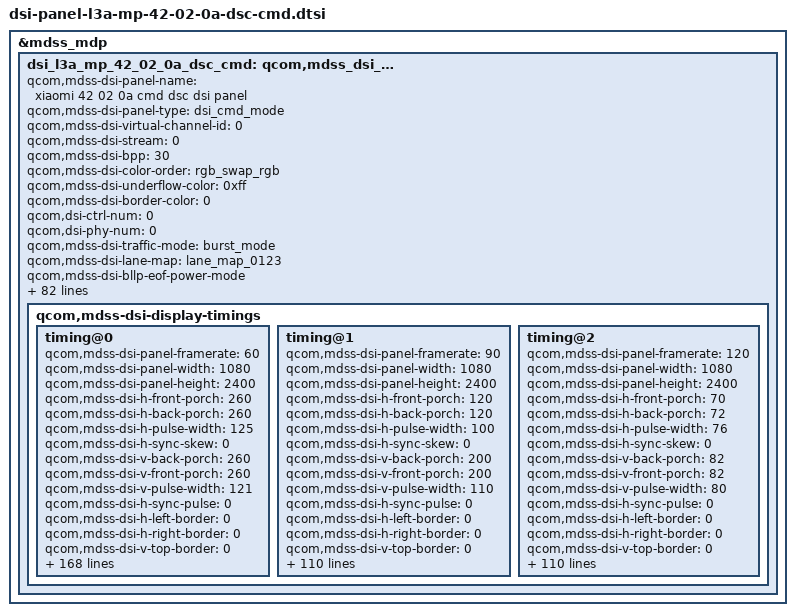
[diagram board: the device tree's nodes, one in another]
&mdss_mdp {
	dsi_l3a_mp_42_02_0a_dsc_cmd: qcom,mdss_dsi_l3a_mp_42_02_0a_dsc_cmd {
		qcom,mdss-dsi-panel-name = "xiaomi 42 02 0a cmd dsc dsi panel";
		qcom,mdss-dsi-panel-type = "dsi_cmd_mode";
		qcom,mdss-dsi-virtual-channel-id = <0>;
		qcom,mdss-dsi-stream = <0>;
		qcom,mdss-dsi-bpp = <30>;
		qcom,mdss-dsi-color-order = "rgb_swap_rgb";
		qcom,mdss-dsi-underflow-color = <0xff>;
		qcom,mdss-dsi-border-color = <0>;

		qcom,dsi-ctrl-num = <0>;
		qcom,dsi-phy-num = <0>;

		qcom,mdss-dsi-traffic-mode = "burst_mode";
		qcom,mdss-dsi-lane-map = "lane_map_0123";
		qcom,mdss-dsi-bllp-eof-power-mode;
		qcom,mdss-dsi-bllp-power-mode;
		qcom,mdss-dsi-lane-0-state;
		qcom,mdss-dsi-lane-1-state;
		qcom,mdss-dsi-lane-2-state;
		qcom,mdss-dsi-lane-3-state;
		qcom,mdss-dsi-dma-trigger = "trigger_sw";
		qcom,mdss-dsi-mdp-trigger = "none";
		qcom,mdss-dsi-reset-sequence = <1 1>, <0 1>, <1 10>;
		qcom,mdss-pan-physical-width-dimension = <654>;
		qcom,mdss-pan-physical-height-dimension = <1454>;
		qcom,mdss-dsi-te-pin-select = <1>;
		qcom,mdss-dsi-wr-mem-start = <0x2c>;
		qcom,mdss-dsi-wr-mem-continue = <0x3c>;
		qcom,mdss-dsi-te-dcs-command = <1>;
		qcom,mdss-dsi-te-check-enable;
		qcom,mdss-dsi-te-using-te-pin;
		qcom,mdss-dsi-tx-eot-append;
		qcom,mdss-dsi-lp11-init;

		qcom,mdss-dsi-panel-hdr-enabled;
		qcom,mdss-dsi-panel-hdr-color-primaries = <14500 15500 32000
			17000 15500 30000 8000 3000>;
		qcom,mdss-dsi-panel-peak-brightness = <4200000>;
		qcom,mdss-dsi-panel-blackness-level = <3230>;

		qcom,bl-update-flag = "delay_until_first_frame";

		qcom,esd-check-enabled;
		qcom,mdss-dsi-panel-status-check-mode = "reg_read";
		qcom,mdss-dsi-panel-status-offset-command = [
			39 00 00 00 00 00 05 FF AA 55 A5 81
			15 01 00 00 00 00 02 6F 0F];
		qcom,mdss-dsi-panel-status-command = [
			06 01 00 01 00 00 01 FA
			06 01 00 01 00 00 01 91];
		qcom,mdss-dsi-panel-status-read-length = <1 18>;
		qcom,mdss-dsi-panel-max-error-count = <3>;
		qcom,mdss-dsi-panel-status-value = <0x00>,
				<0xAB 0x28 0x00 0x0C 0xC2 0x00 0x03 0x1C 0x01 0x7E 0x00 0x0F 0x08 0xBB 0x04 0x3D 0x10 0xF0>;
		qcom,mdss-dsi-panel-status-command-state = "dsi_lp_mode";
		qcom,mdss-dsi-panel-status-offset-command-state = "dsi_lp_mode";

		qcom,mdss-dsi-display-timings {
			timing@0{
				qcom,mdss-dsi-panel-framerate = <60>;
				qcom,mdss-dsi-panel-width = <1080>;
				qcom,mdss-dsi-panel-height = <2400>;
				qcom,mdss-dsi-h-front-porch = <260>;
				qcom,mdss-dsi-h-back-porch = <260>;
				qcom,mdss-dsi-h-pulse-width = <125>;
				qcom,mdss-dsi-h-sync-skew = <0>;
				qcom,mdss-dsi-v-back-porch = <260>;
				qcom,mdss-dsi-v-front-porch = <260>;
				qcom,mdss-dsi-v-pulse-width = <121>;
				qcom,mdss-dsi-h-sync-pulse = <0>;
				qcom,mdss-dsi-h-left-border = <0>;
				qcom,mdss-dsi-h-right-border = <0>;
				qcom,mdss-dsi-v-top-border = <0>;
				qcom,mdss-dsi-v-bottom-border = <0>;
				qcom,mdss-dsi-panel-clockrate = <1100000000>;
				qcom,mdss-dsi-panel-jitter = <0x5 0x1>;
				qcom,mdss-mdp-transfer-time-us = <8000>;
				qcom,mdss-dsi-on-command = [
					39 00 00 00 00 00 06 F0 55 AA 52 08 00
					15 00 00 00 00 00 02 6F 29
					15 00 00 00 00 00 02 D9 00
					15 00 00 00 00 00 02 6F 01
					15 00 00 00 00 00 02 D9 80
					15 00 00 00 00 00 02 6F 07
					39 00 00 00 00 00 03 B2 07 FF
					15 00 00 00 00 00 02 6F 17
					39 00 00 00 00 00 03 B2 07 FF
					15 00 00 00 00 00 02 6F 1F
					39 01 00 00 00 00 03 B2 00 50
					39 00 00 00 00 00 06 F0 55 AA 52 08 07
					/*round for FPR*/
					39 00 00 00 00 00 2C C9 21 00 27 D9 27 D9 00 00 3F E0 8E C6 3F E0 8E C6 80 06 33 D5 F1 00 16 13 00 7B 78 33 D0 27 D9 0F 9B 9B 00 00 00 00 00 00 00 00 00
					39 00 00 00 00 00 2C CA 27 00 27 D9 27 D9 00 00 00 00 00 00 3F E0 8E C6 80 00 00 00 00 00 7C 13 00 E1 78 33 D0 00 00 03 65 9B 00 00 00 00 00 00 00 00 00
					39 00 00 00 00 00 2C CB 2D 00 27 D9 27 D9 00 00 3F E0 8E C6 80 00 00 00 00 00 00 00 00 00 16 79 00 7B DE 33 70 00 00 0C 9B 65 00 00 00 00 00 00 00 00 00
					39 01 00 00 00 00 2C CC 2B 00 27 D9 27 D9 00 00 00 00 00 00 80 00 00 00 7F F9 CC 2A 0F 00 7C 79 00 E1 DE 33 7F D8 27 00 65 65 00 00 00 00 00 00 00 00 00
					39 00 00 00 00 00 02 CD 00
					39 00 00 00 00 00 02 CE 00
					39 00 00 00 00 00 02 CF 00
					39 01 00 00 00 00 02 D0 00
					39 00 00 00 00 00 02 C1 00
					39 00 00 00 00 00 02 C2 00
					39 00 00 00 00 00 02 C3 00
					39 00 00 00 00 00 02 C4 00
					39 00 00 00 00 00 02 C5 00
					39 00 00 00 00 00 02 C6 00
					39 00 00 00 00 00 02 C7 00
					39 01 00 00 00 00 02 C8 00
					39 01 00 00 00 00 03 C0 05 02
					15 00 00 00 00 00 02 90 01	// VESA ON
					/* Choose VESA Edition */
					39 00 00 00 00 00 13 91	AB 28 00 0C C2 00 03 1C 01 7E 00 0F 08 BB 04 3D 10 F0	// DSC Setting
					15 01 00 00 00 00 02 03 01
					15 01 00 00 00 00 02 35 00	// TE ON
					39 01 00 00 00 00 05 2A 00 00 04 37
					39 01 00 00 00 00 05 2B 00 00 09 5F
					15 01 00 00 00 00 02 53 20
					15 01 00 00 00 00 02 2F 01
					15 01 00 00 00 00 02 26 01
					39 00 00 00 00 00 06 F0 55 AA 52 08 01
					39 01 00 00 00 00 08 C3 9B 01 94 D0 22 02 00
					39 01 00 00 00 00 05 FF AA 55 A5 80
					39 01 00 00 00 00 02 6F 61
					39 01 00 00 00 00 02 F3 80
					39 01 00 00 00 00 06 F0 55 AA 52 08 00
					39 01 00 00 00 00 02 C0 46
					39 01 00 00 00 00 02 6F 08
					39 01 00 00 00 00 02 B5 32
					39 01 00 00 00 00 02 6F 0B
					39 01 00 00 00 00 04 B5 33 23 2B
					39 01 00 00 00 00 06 F0 55 AA 52 08 01
					39 01 00 00 00 00 02 6F 01
					39 01 00 00 00 00 04 D2 00 00 11
					39 01 00 00 00 00 02 6F 06
					39 01 00 00 00 00 02 D2 05
					39 01 00 00 00 00 02 6F 0F
					39 01 00 00 00 00 02 D2 00
					39 01 00 00 00 00 02 6F 09
					39 01 00 00 00 00 03 D2 00 00
					39 01 00 00 00 00 02 CE 00
					39 01 00 00 00 00 06 F0 55 AA 52 08 05
					39 00 00 00 00 00 02 CA 11
					39 01 00 00 00 00 04 CB 22 22 22
					/* Sleep Out */
					05 01 00 00 50 00 02 11 00
					/* Display On */
					05 01 00 00 00 00 02 29 00];
				qcom,mdss-dsi-off-command = [
					05 01 00 00 00 00 02 28 00
					05 01 00 00 78 00 02 10 00];
				qcom,mdss-dsi-on-command-state = "dsi_lp_mode";
				qcom,mdss-dsi-off-command-state = "dsi_lp_mode";

				qcom,mdss-dsi-timing-switch-command = [
					/* Enter 60Hz */
					15 01 00 00 00 00 02 2F 01
					15 01 00 00 00 00 02 26 01];
				qcom,mdss-dsi-timing-switch-command-state = "dsi_lp_mode";

				qcom,mdss-dsi-nolp-command = [
					/* Aod to Normal */
					39 01 00 00 00 00 06 F0 55 AA 52 08 00 /* Set page 0 */
					39 01 00 00 00 00 02 B2 18
					05 01 00 00 00 00 02 38 00];
				qcom,mdss-dsi-nolp-command-state = "dsi_lp_mode";

				qcom,compression-mode = "dsc";
				qcom,mdss-dsc-version = <0x11>;
				qcom,mdss-dsc-scr-version = <0x0>;
				qcom,mdss-dsc-slice-height = <12>;
				qcom,mdss-dsc-slice-width = <1080>;
				qcom,mdss-dsc-slice-per-pkt = <2>;
				qcom,mdss-dsc-bit-per-component = <10>;
				qcom,mdss-dsc-bit-per-pixel = <8>;
				qcom,mdss-dsc-block-prediction-enable;
			};
			timing@1{
				qcom,mdss-dsi-panel-framerate = <90>;
				qcom,mdss-dsi-panel-width = <1080>;
				qcom,mdss-dsi-panel-height = <2400>;
				qcom,mdss-dsi-h-front-porch = <120>;
				qcom,mdss-dsi-h-back-porch = <120>;
				qcom,mdss-dsi-h-pulse-width = <100>;
				qcom,mdss-dsi-h-sync-skew = <0>;
				qcom,mdss-dsi-v-back-porch = <200>;
				qcom,mdss-dsi-v-front-porch = <200>;
				qcom,mdss-dsi-v-pulse-width = <110>;
				qcom,mdss-dsi-h-sync-pulse = <0>;
				qcom,mdss-dsi-h-left-border = <0>;
				qcom,mdss-dsi-h-right-border = <0>;
				qcom,mdss-dsi-v-top-border = <0>;
				qcom,mdss-dsi-v-bottom-border = <0>;
				qcom,mdss-dsi-panel-clockrate = <1100000000>;
				qcom,mdss-dsi-panel-jitter = <0x5 0x1>;
				qcom,mdss-mdp-transfer-time-us = <9500>;
				qcom,mdss-dsi-on-command = [
					39 00 00 00 00 00 06 F0 55 AA 52 08 00
					15 00 00 00 00 00 02 6F 29
					15 00 00 00 00 00 02 D9 00
					15 00 00 00 00 00 02 6F 01
					15 00 00 00 00 00 02 D9 80
					15 00 00 00 00 00 02 6F 07
					39 00 00 00 00 00 03 B2 07 FF
					15 00 00 00 00 00 02 6F 17
					39 00 00 00 00 00 03 B2 07 FF
					15 00 00 00 00 00 02 6F 1F
					39 01 00 00 00 00 03 B2 00 50
					39 00 00 00 00 00 06 F0 55 AA 52 08 07
					/*round for FPR*/
					39 00 00 00 00 00 2C C9 21 00 27 D9 27 D9 00 00 3F E0 8E C6 3F E0 8E C6 80 06 33 D5 F1 00 16 13 00 7B 78 33 D0 27 D9 0F 9B 9B 00 00 00 00 00 00 00 00 00
					39 00 00 00 00 00 2C CA 27 00 27 D9 27 D9 00 00 00 00 00 00 3F E0 8E C6 80 00 00 00 00 00 7C 13 00 E1 78 33 D0 00 00 03 65 9B 00 00 00 00 00 00 00 00 00
					39 00 00 00 00 00 2C CB 2D 00 27 D9 27 D9 00 00 3F E0 8E C6 80 00 00 00 00 00 00 00 00 00 16 79 00 7B DE 33 70 00 00 0C 9B 65 00 00 00 00 00 00 00 00 00
					39 01 00 00 00 00 2C CC 2B 00 27 D9 27 D9 00 00 00 00 00 00 80 00 00 00 7F F9 CC 2A 0F 00 7C 79 00 E1 DE 33 7F D8 27 00 65 65 00 00 00 00 00 00 00 00 00
					39 00 00 00 00 00 02 CD 00
					39 00 00 00 00 00 02 CE 00
					39 00 00 00 00 00 02 CF 00
					39 01 00 00 00 00 02 D0 00
					39 00 00 00 00 00 02 C1 00
					39 00 00 00 00 00 02 C2 00
					39 00 00 00 00 00 02 C3 00
					39 00 00 00 00 00 02 C4 00
					39 00 00 00 00 00 02 C5 00
					39 00 00 00 00 00 02 C6 00
					39 00 00 00 00 00 02 C7 00
					39 01 00 00 00 00 02 C8 00
					39 01 00 00 00 00 03 C0 05 02
					15 00 00 00 00 00 02 90 01	// VESA ON
					/* Choose VESA Edition */
					39 00 00 00 00 00 13 91	AB 28 00 0C C2 00 03 1C 01 7E 00 0F 08 BB 04 3D 10 F0	// DSC Setting
					15 01 00 00 00 00 02 03 01
					15 01 00 00 00 00 02 35 00	// TE ON
					39 01 00 00 00 00 05 2A 00 00 04 37
					39 01 00 00 00 00 05 2B 00 00 09 5F
					15 01 00 00 00 00 02 53 20
					15 01 00 00 00 00 02 2F 03
					39 00 00 00 00 00 06 F0 55 AA 52 08 00
					15 00 00 00 00 00 02 6F 0A
					15 01 00 00 00 00 02 C0 01
					39 00 00 00 00 00 06 F0 55 AA 52 08 02
					15 00 00 00 00 00 02 CC 30
					15 00 00 00 14 00 02 CE 01
					15 01 00 00 00 00 02 CC 00
					39 00 00 00 00 00 06 F0 55 AA 52 08 01
					39 01 00 00 00 00 08 C3 9B 01 94 D0 22 02 00
					39 01 00 00 00 00 05 FF AA 55 A5 80
					39 01 00 00 00 00 02 6F 61
					39 01 00 00 00 00 02 F3 80
					39 01 00 00 00 00 06 F0 55 AA 52 08 00
					39 01 00 00 00 00 02 C0 46
					39 01 00 00 00 00 02 6F 08
					39 01 00 00 00 00 02 B5 32
					39 01 00 00 00 00 02 6F 0B
					39 01 00 00 00 00 04 B5 33 23 2B
					39 01 00 00 00 00 06 F0 55 AA 52 08 01
					39 01 00 00 00 00 02 6F 01
					39 01 00 00 00 00 04 D2 00 00 11
					39 01 00 00 00 00 02 6F 06
					39 01 00 00 00 00 02 D2 05
					39 01 00 00 00 00 02 6F 0F
					39 01 00 00 00 00 02 D2 00
					39 01 00 00 00 00 02 6F 09
					39 01 00 00 00 00 03 D2 00 00
					39 01 00 00 00 00 02 CE 00
					39 01 00 00 00 00 06 F0 55 AA 52 08 05
					39 00 00 00 00 00 02 CA 11
					39 01 00 00 00 00 04 CB 22 22 22
					/* Sleep Out */
					05 01 00 00 50 00 02 11 00
					/* Display On */
					05 01 00 00 00 00 02 29 00];
				qcom,mdss-dsi-off-command = [
					05 01 00 00 00 00 02 28 00
					05 01 00 00 78 00 02 10 00];
				qcom,mdss-dsi-on-command-state = "dsi_lp_mode";
				qcom,mdss-dsi-off-command-state = "dsi_lp_mode";

				qcom,mdss-dsi-timing-switch-command = [
					/* Enter 90Hz */
					39 01 00 00 00 00 02 2F 03
					39 00 00 00 00 00 06 F0 55 AA 52 08 00
					39 00 00 00 00 00 02 6F 0A
					39 00 00 00 00 00 02 C0 01
					39 00 00 00 00 00 06 F0 55 AA 52 08 02
					39 00 00 00 00 00 02 CC 30
					39 01 00 00 0A 00 02 CE 01
					39 01 00 00 00 00 02 CC 00];
				qcom,mdss-dsi-timing-switch-command-state = "dsi_lp_mode";

				qcom,mdss-dsi-nolp-command = [
					/* Aod to Normal */
					39 01 00 00 00 00 06 F0 55 AA 52 08 00 /* Set page 0 */
					39 01 00 00 00 00 02 B2 18
					05 01 00 00 00 00 02 38 00
					15 01 00 00 00 00 02 2F 03];
				qcom,mdss-dsi-nolp-command-state = "dsi_lp_mode";

				qcom,compression-mode = "dsc";
				qcom,mdss-dsc-version = <0x11>;
				qcom,mdss-dsc-scr-version = <0x0>;
				qcom,mdss-dsc-slice-height = <12>;
				qcom,mdss-dsc-slice-width = <1080>;
				qcom,mdss-dsc-slice-per-pkt = <2>;
				qcom,mdss-dsc-bit-per-component = <10>;
				qcom,mdss-dsc-bit-per-pixel = <8>;
				qcom,mdss-dsc-block-prediction-enable;
			};
			timing@2{
				qcom,mdss-dsi-panel-framerate = <120>;
				qcom,mdss-dsi-panel-width = <1080>;
				qcom,mdss-dsi-panel-height = <2400>;
				qcom,mdss-dsi-h-front-porch = <70>;
				qcom,mdss-dsi-h-back-porch = <72>;
				qcom,mdss-dsi-h-pulse-width = <76>;
				qcom,mdss-dsi-h-sync-skew = <0>;
				qcom,mdss-dsi-v-back-porch = <82>;
				qcom,mdss-dsi-v-front-porch = <82>;
				qcom,mdss-dsi-v-pulse-width = <80>;
				qcom,mdss-dsi-h-sync-pulse = <0>;
				qcom,mdss-dsi-h-left-border = <0>;
				qcom,mdss-dsi-h-right-border = <0>;
				qcom,mdss-dsi-v-top-border = <0>;
				qcom,mdss-dsi-v-bottom-border = <0>;
				qcom,mdss-dsi-panel-clockrate = <1100000000>;
				qcom,mdss-dsi-panel-jitter = <0x5 0x1>;
				qcom,mdss-mdp-transfer-time-us = <6000>;
				qcom,mdss-dsi-on-command = [
					39 00 00 00 00 00 06 F0 55 AA 52 08 00
					15 00 00 00 00 00 02 6F 29
					15 00 00 00 00 00 02 D9 00
					15 00 00 00 00 00 02 6F 01
					15 00 00 00 00 00 02 D9 80
					15 00 00 00 00 00 02 6F 07
					39 00 00 00 00 00 03 B2 07 FF
					15 00 00 00 00 00 02 6F 17
					39 00 00 00 00 00 03 B2 07 FF
					15 00 00 00 00 00 02 6F 1F
					39 01 00 00 00 00 03 B2 00 50
					39 00 00 00 00 00 06 F0 55 AA 52 08 07
					/*round for FPR*/
					39 00 00 00 00 00 2C C9 21 00 27 D9 27 D9 00 00 3F E0 8E C6 3F E0 8E C6 80 06 33 D5 F1 00 16 13 00 7B 78 33 D0 27 D9 0F 9B 9B 00 00 00 00 00 00 00 00 00
					39 00 00 00 00 00 2C CA 27 00 27 D9 27 D9 00 00 00 00 00 00 3F E0 8E C6 80 00 00 00 00 00 7C 13 00 E1 78 33 D0 00 00 03 65 9B 00 00 00 00 00 00 00 00 00
					39 00 00 00 00 00 2C CB 2D 00 27 D9 27 D9 00 00 3F E0 8E C6 80 00 00 00 00 00 00 00 00 00 16 79 00 7B DE 33 70 00 00 0C 9B 65 00 00 00 00 00 00 00 00 00
					39 01 00 00 00 00 2C CC 2B 00 27 D9 27 D9 00 00 00 00 00 00 80 00 00 00 7F F9 CC 2A 0F 00 7C 79 00 E1 DE 33 7F D8 27 00 65 65 00 00 00 00 00 00 00 00 00
					39 00 00 00 00 00 02 CD 00
					39 00 00 00 00 00 02 CE 00
					39 00 00 00 00 00 02 CF 00
					39 01 00 00 00 00 02 D0 00
					39 00 00 00 00 00 02 C1 00
					39 00 00 00 00 00 02 C2 00
					39 00 00 00 00 00 02 C3 00
					39 00 00 00 00 00 02 C4 00
					39 00 00 00 00 00 02 C5 00
					39 00 00 00 00 00 02 C6 00
					39 00 00 00 00 00 02 C7 00
					39 01 00 00 00 00 02 C8 00
					39 01 00 00 00 00 03 C0 05 02
					15 00 00 00 00 00 02 90 01	// VESA ON
					/* Choose VESA Edition */
					39 00 00 00 00 00 13 91	AB 28 00 0C C2 00 03 1C 01 7E 00 0F 08 BB 04 3D 10 F0	// DSC Setting
					15 01 00 00 00 00 02 03 01
					15 01 00 00 00 00 02 35 00	// TE ON
					39 01 00 00 00 00 05 2A 00 00 04 37
					39 01 00 00 00 00 05 2B 00 00 09 5F
					15 01 00 00 00 00 02 53 20
					15 01 00 00 00 00 02 2F 02
					39 00 00 00 00 00 06 F0 55 AA 52 08 00
					15 00 00 00 00 00 02 6F 09
					15 01 00 00 00 00 02 C0 20
					39 00 00 00 00 00 06 F0 55 AA 52 08 02
					15 00 00 00 00 00 02 CC 30
					15 00 00 00 14 00 02 CE 01
					15 01 00 00 00 00 02 CC 00
					39 00 00 00 00 00 06 F0 55 AA 52 08 01
					39 01 00 00 00 00 08 C3 9B 01 94 D0 22 02 00
					39 01 00 00 00 00 05 FF AA 55 A5 80
					39 01 00 00 00 00 02 6F 61
					39 01 00 00 00 00 02 F3 80
					39 01 00 00 00 00 06 F0 55 AA 52 08 00
					39 01 00 00 00 00 02 C0 46
					39 01 00 00 00 00 02 6F 08
					39 01 00 00 00 00 02 B5 32
					39 01 00 00 00 00 02 6F 0B
					39 01 00 00 00 00 04 B5 33 23 2B
					39 01 00 00 00 00 06 F0 55 AA 52 08 01
					39 01 00 00 00 00 02 6F 01
					39 01 00 00 00 00 04 D2 00 00 11
					39 01 00 00 00 00 02 6F 06
					39 01 00 00 00 00 02 D2 05
					39 01 00 00 00 00 02 6F 0F
					39 01 00 00 00 00 02 D2 00
					39 01 00 00 00 00 02 6F 09
					39 01 00 00 00 00 03 D2 00 00
					39 01 00 00 00 00 02 CE 00
					39 01 00 00 00 00 06 F0 55 AA 52 08 05
					39 00 00 00 00 00 02 CA 11
					39 01 00 00 00 00 04 CB 22 22 22
					/* Sleep Out */
					05 01 00 00 50 00 02 11 00
					/* Display On */
					05 01 00 00 00 00 02 29 00];
				qcom,mdss-dsi-off-command = [
					05 01 00 00 00 00 02 28 00
					05 01 00 00 78 00 02 10 00];
				qcom,mdss-dsi-on-command-state = "dsi_lp_mode";
				qcom,mdss-dsi-off-command-state = "dsi_lp_mode";

				qcom,mdss-dsi-timing-switch-command = [
					/* Enter 120Hz */
					39 01 00 00 00 00 02 2F 02
					39 00 00 00 00 00 06 F0 55 AA 52 08 00
					39 00 00 00 00 00 02 6F 09
					39 00 00 00 00 00 02 C0 20
					39 00 00 00 00 00 06 F0 55 AA 52 08 02
					39 00 00 00 00 00 02 CC 30
					39 01 00 00 0A 00 02 CE 01
					39 01 00 00 00 00 02 CC 00];
				qcom,mdss-dsi-timing-switch-command-state = "dsi_lp_mode";

				qcom,mdss-dsi-nolp-command = [
					/* Aod to Normal */
					39 01 00 00 00 00 06 F0 55 AA 52 08 00 /* Set page 0 */
					39 01 00 00 00 00 02 B2 18
					05 01 00 00 00 00 02 38 00
					/* Enter 120Hz */
					15 01 00 00 00 00 02 2F 02];
				qcom,mdss-dsi-nolp-command-state = "dsi_lp_mode";

				qcom,compression-mode = "dsc";
				qcom,mdss-dsc-version = <0x11>;
				qcom,mdss-dsc-scr-version = <0x0>;
				qcom,mdss-dsc-slice-height = <12>;
				qcom,mdss-dsc-slice-width = <1080>;
				qcom,mdss-dsc-slice-per-pkt = <2>;
				qcom,mdss-dsc-bit-per-component = <10>;
				qcom,mdss-dsc-bit-per-pixel = <8>;
				qcom,mdss-dsc-block-prediction-enable;
			};
		};
	};
};

&dsi_l3a_mp_42_02_0a_dsc_cmd {
	mi,panel-id = <0x4C3341 0x00420200>;
	mi,feature-enabled;
	mi,mdss-dsi-bl-dcs-big-endian-type;
	/* IRQF_ONESHOT | IRQF_TRIGGER_RISING */
	/* trig-flags: falling-0x0002 rasing-0x0001 */
	mi,esd-err-irq-gpio = <&tlmm 51 0x2002>;

	/* White Color Coordinate */
	mi,mdss-dsi-white-point-read-enabled;
	mi,mdss-dsi-white-point-register-read-length = <8>;
	mi,mdss-dsi-white-point-info-index = <0>;
	mi,mdss-dsi-white-point-info-length = <8>;

	mi,mdss-dsi-panel-dc-type = <0>;
	mi,mdss-dsi-panel-dc-update-flag-v2;
	mi,mdss-dsi-panel-dc-on-update-d2-index = <10>;
	mi,mdss-dsi-panel-dc-off-update-d2-index = <6>;

	mi,mdss-panel-on-dimming-delay = <120>;

	mi,doze-hbm-dbv-level = <245>;
	mi,doze-lbm-dbv-level = <20>;

	mi,local-hbm-enabled;
	mi,mdss-dsi-panel-fod-lhbm-87reg-ctrl-flag;
	mi,mdss-dsi-panel-fod-lhbm-white-1000nit-87reg-index = <7>;
	mi,mdss-dsi-panel-fod-lhbm-white-110nit-87reg-index = <7>;
	mi,mdss-dsi-panel-fod-lhbm-green-500nit-87reg-index = <4>;

	//mi,mdss-dsi-panel-fod-lhbm-green-500nit-update-flag;
	//mi,mdss-dsi-panel-fod-lhbm-green-500nit-update-d0-index = <2>;

	mi,mdss-dsi-panel-fod-lhbm-white-update-flag;
	mi,mdss-dsi-panel-fod-lhbm-white-1000nit-update-d0-index = <5>;
	mi,mdss-dsi-panel-fod-lhbm-white-110nit-update-d0-index = <5>;

	mi,mdss-dsi-panel-fod-lhbm-b2reg-ctrl-flag;
	mi,mdss-dsi-panel-fod-lhbm-white-1000nit-b2reg-index = <1>;
	mi,mdss-dsi-panel-fod-lhbm-white-110nit-b2reg-index = <1>;

	mi,mdss-dsi-panel-nolp-b2reg-ctrl-flag;
	mi,mdss-dsi-panel-nolp-b2reg-index = <1>;

	mi,mdss-dsi-panel-gir-update-flag;
	mi,mdss-dsi-panel-gir-on-update-b9-index = <2>;

/*aod status enter lp1 not on start*/
	mi,mdss-dsi-panel-fod-dimlayer-enabled;
	mi,mdss-dsi-dimlayer-brightness-alpha-lut-item-count = <21>;
	mi,mdss-dsi-dimlayer-brightness-alpha-lut =
	/* brightness  alpha */
		<0          0xFF
		 4          0xEB
		 8          0xEA
		 12         0xE9
		 13         0xE8
		 20         0xE5
		 24         0xE3
		 30         0xE0
		 68         0xD0
		 133        0xC0
		 218        0xB0
		 328        0xA0
		 486        0x90
		 642        0x80
		 832        0x70
		 1043       0x60
		 1267       0x50
		 1500       0x40
		 1770       0x30
		 2000       0x24
		 2047       0x21>;
/*aod status enter lp1 not on end*/

	qcom,mdss-dsi-display-timings {
		timing@0{
			mi,mdss-dsi-doze-hbm-command = [
				/* Enter 60Hz */
				39 01 00 00 00 00 02 2F 01
				39 01 00 00 00 00 02 26 01
				/* AOD Mode On */
				39 01 00 00 00 00 06 F0 55 AA 52 08 00
				39 01 00 00 00 00 02 B2 08
				/* 60 nit*/
				39 01 00 00 00 00 02 6F 02
				39 01 00 00 00 00 03 51 0F FF
				05 01 00 00 0A 00 02 39 00];
			mi,mdss-dsi-doze-lbm-command = [
				/* Enter 60Hz */
				39 01 00 00 00 00 02 2F 01
				39 01 00 00 00 00 02 26 01
				/* AOD Mode On */
				39 01 00 00 00 00 06 F0 55 AA 52 08 00
				39 01 00 00 00 00 02 B2 08
				/* 5 nit */
				39 01 00 00 00 00 02 6F 02
				39 01 00 00 00 00 03 51 01 55
				05 01 00 00 0A 00 02 39 00];
			mi,mdss-dsi-doze-hbm-command-state = "dsi_lp_mode";
			mi,mdss-dsi-doze-lbm-command-state = "dsi_lp_mode";

			mi,mdss-dsi-hbm-on-command = [
				/* Dimming On */
				15 00 00 00 00 00 02 53 28
				/* HBM Mode 800 nit */
				39 01 00 00 00 00 05 51 0F FF 00 00];
			mi,mdss-dsi-hbm-off-command = [
				/* Dimming On */
				15 00 00 00 00 00 02 53 28
				/* Normal Mode */
				/* parameter will be updated base on last brightness */
				39 01 00 00 00 00 05 51 07 FF 00 00];
			mi,mdss-dsi-hbm-on-command-state = "dsi_lp_mode";
			mi,mdss-dsi-hbm-off-command-state = "dsi_lp_mode";

			mi,mdss-dsi-fod-lhbm-green-500nit-read-pre-command = [
				39 01 00 00 00 00 06 F0 55 AA 52 08 02
				39 00 00 00 00 00 02 BF 19
				39 00 00 00 00 00 02 6F 04];
			mi,mdss-dsi-fod-lhbm-green-500nit-read-pre-command-state = "dsi_lp_mode";
			mi,mdss-dsi-fod-lhbm-green-500nit-read-command = [
				06 01 00 00 00 00 02 B5 00];
			mi,mdss-dsi-fod-lhbm-green-500nit-read-command-state = "dsi_lp_mode";
			mi,mdss-dsi-fod-lhbm-white-1000nit-giroff-read-pre-command = [
				39 01 00 00 00 00 06 F0 55 AA 52 08 02
				39 01 00 00 00 00 02 BF 19];
			mi,mdss-dsi-fod-lhbm-white-1000nit-giroff-read-pre-command-state = "dsi_lp_mode";
			mi,mdss-dsi-fod-lhbm-white-1000nit-giron-read-pre-command = [
				39 01 00 00 00 00 06 F0 55 AA 52 08 02
				39 01 00 00 00 00 02 BF 39];
			mi,mdss-dsi-fod-lhbm-white-1000nit-giron-read-pre-command-state = "dsi_lp_mode";
			mi,mdss-dsi-fod-lhbm-white-110nit-giroff-read-pre-command = [
				39 01 00 00 00 00 06 F0 55 AA 52 08 02
				39 01 00 00 00 00 02 BF 17];
			mi,mdss-dsi-fod-lhbm-white-110nit-giroff-read-pre-command-state = "dsi_lp_mode";
			mi,mdss-dsi-fod-lhbm-white-110nit-giron-read-pre-command = [
				39 01 00 00 00 00 06 F0 55 AA 52 08 02
				39 01 00 00 00 00 02 BF 37];
			mi,mdss-dsi-fod-lhbm-white-110nit-giron-read-pre-command-state = "dsi_lp_mode";
			mi,mdss-dsi-fod-lhbm-white-1000nit-read-offest-command = [
				39 01 00 00 00 00 02 6F 08];
			mi,mdss-dsi-fod-lhbm-white-1000nit-read-offest-command-state = "dsi_lp_mode";
			mi,mdss-dsi-fod-lhbm-white-110nit-read-offest-command = [
				39 01 00 00 00 00 02 6F 02];
			mi,mdss-dsi-fod-lhbm-white-110nit-read-offest-command-state = "dsi_lp_mode";
			mi,mdss-dsi-fod-lhbm-white-read-B2-command = [
				06 01 00 00 00 00 02 B2 00];
			mi,mdss-dsi-fod-lhbm-white-read-B2-command-state = "dsi_lp_mode";
			mi,mdss-dsi-fod-lhbm-white-read-B5-command = [
				06 01 00 00 00 00 02 B5 00];
			mi,mdss-dsi-fod-lhbm-white-read-B5-command-state = "dsi_lp_mode";
			mi,mdss-dsi-fod-lhbm-white-read-B8-command = [
				06 01 00 00 00 00 02 B8 00];
			mi,mdss-dsi-fod-lhbm-white-read-B8-command-state = "dsi_lp_mode";

			mi,mdss-dsi-fod-lhbm-white-1000nit-command = [
				39 01 00 00 00 00 06 F0 55 AA 52 08 00 /* Set page 0 */
				39 01 00 00 00 00 02 B2 18
				05 01 00 00 00 00 02 38 00
				39 01 00 00 00 00 06 F0 55 AA 52 08 02
				39 01 00 00 00 00 02 6F 08
				/*FPR area RGB[11:0] setting*/
				39 01 00 00 00 00 07 D0 0B 00 09 92 0B 0E
				/*FPR center postion x[11:0], y[11:0]*/
				39 01 00 00 00 00 05 88 02 1C 08 73
				/*alpha for AA*/
				39 01 00 00 00 00 03 87 0F FF
				39 01 00 00 00 00 02 6F 02
				39 01 00 00 32 00 02 87 05];
			mi,mdss-dsi-fod-lhbm-white-110nit-command = [
				39 01 00 00 00 00 06 F0 55 AA 52 08 00 /* Set page 0 */
				39 01 00 00 00 00 02 B2 18
				05 01 00 00 00 00 02 38 00
				39 01 00 00 00 00 06 F0 55 AA 52 08 02
				39 01 00 00 00 00 02 6F 08
				/*FPR area RGB[11:0] setting*/
				39 01 00 00 00 00 07 D0 07 13 06 49 07 A4
				/*FPR center postion x[11:0], y[11:0]*/
				39 01 00 00 00 00 05 88 02 1C 08 73
				/*alpha for AA*/
				39 01 00 00 00 00 03 87 0F FF
				39 01 00 00 00 00 02 6F 02
				39 01 00 00 32 00 02 87 05];
			mi,mdss-dsi-fod-lhbm-green-500nit-command = [
				39 01 00 00 00 00 06 F0 55 AA 52 08 02
				39 01 00 00 00 00 02 6F 08
				/*FPR area RGB[11:0] setting*/
				39 01 00 00 00 00 07 D0 00 00 08 A8 00 00
				/*FPR center postion x[11:0], y[11:0]*/
				39 01 00 00 00 00 05 88 02 1C 08 73
				/*alpha for AA*/
				39 01 00 00 00 00 03 87 0F FF
				39 01 00 00 00 00 02 6F 02
				39 01 00 00 32 00 02 87 05];
			mi,mdss-dsi-fod-lhbm-off-command = [
				39 01 00 00 00 00 02 6F 02
				39 01 00 00 00 00 02 87 04];
			mi,mdss-dsi-fod-lhbm-white-1000nit-command-state = "dsi_lp_mode";
			mi,mdss-dsi-fod-lhbm-white-110nit-command-state = "dsi_lp_mode";
			mi,mdss-dsi-fod-lhbm-green-500nit-command-state = "dsi_lp_mode";
			mi,mdss-dsi-fod-lhbm-off-command-state = "dsi_lp_mode";

			mi,mdss-dsi-hbm-hdr-on-command = [
				/* VI Setting voltage -3.5V */
				39 01 00 00 00 00 06 F0 55 AA 52 08 01 /* Set page 1 */
				39 00 00 00 00 00 09 B9 1F 1F 1F 1F 1F 1F 1F 1F
				/* Dimming On */
				15 00 00 00 00 00 02 53 28
				/* HBM Mode 800 nit */
				39 01 00 00 00 00 05 51 0F FF 00 00
				/* ELVSS SWIRE =-4.5V */
				15 01 00 00 00 00 02 6F 07
				15 01 00 00 00 00 02 B5 0A];
			mi,mdss-dsi-hbm-hdr-off-command = [
				/* Dimming On */
				15 01 00 00 00 00 02 53 28
				/* Normal Mode */
				/* parameter will be updated base on last brightness */
				39 01 00 00 00 00 05 51 07 FF 00 00];
			mi,mdss-dsi-hbm-hdr-on-command-state = "dsi_lp_mode";
			mi,mdss-dsi-hbm-hdr-off-command-state = "dsi_lp_mode";

			mi,mdss-dsi-dimmingon-command = [15 01 00 00 00 00 02 53 28];
			mi,mdss-dsi-dimmingon-command-state = "dsi_lp_mode";
			mi,mdss-dsi-dimmingoff-command = [15 01 00 00 00 00 02 53 20];
			mi,mdss-dsi-dimmingoff-command-state = "dsi_lp_mode";

			mi,mdss-dsi-white-point-read-command = [06 01 00 00 01 00 02 DF 00];
			mi,mdss-dsi-white-point-read-command-state = "dsi_lp_mode";

			mi,mdss-dsi-switch-page4-command = [
				/* Set page 4 */
				39 01 00 00 00 00 06 F0 55 AA 52 08 04];
			mi,mdss-dsi-dc-read-d2-command = [
				/* Read DC_LUT */
				06 01 00 00 00 00 02 D2 00];
			mi,mdss-dsi-switch-page4-command-state = "dsi_lp_mode";
			mi,mdss-dsi-dc-read-d2-command-state = "dsi_lp_mode";

			mi,mdss-dsi-dc-on-command = [
				39 01 00 00 00 00 06 F0 55 AA 52 08 00 /* Set page 0 */
				39 00 00 00 00 00 02 B2 98
				39 00 00 00 00 00 02 6F 0F
				39 00 00 00 00 00 05 B2 00 00 01 47
				39 00 00 00 00 00 25 B3 00 00 00 00 00 00 00 00 00 00 00 00 00 00 00 00 00 00 00 00 00 00 00 00 01 47 03 33 03 33 07 FF 07 FF 0F FF
				39 00 00 00 00 00 02 6F AC
				39 00 00 00 00 00 47 B2
					00 00 02 FD 04 47 05 40 06 03 06 AD 07 4A 07 D3 08 57 08 CD 09 41 09 A9 0A
					11 0A 71 0A D0 0B 27 0B 7F 0B D1 0C 20 0C 70 0C BA 0D 06 0D 4C 0D 94 0D D7
					0E 1C 0E 5C 0E 9D 0E DB 0F 1A 0F 55 0F 92 0F CB 0F E2 0F FF
				39 00 00 00 00 00 02 6F 52
				39 01 00 00 00 00 45 B3
					00 08 00 12 00 1C 00 26 00 30 00 3A 00 44 00 4E 00 58 00 62 00 6C 00 76 00
					80 00 8A 00 94 00 9E 00 A8 00 B2 00 BC 00 C6 00 D0 00 DA 00 E4 00 EE 00 F8
					01 02 01 0C 01 16 01 20 01 2A 01 34 01 3E 01 42 01 47
				39 00 00 00 00 00 06 F0 55 AA 52 08 04 /* Set page 4 */
				39 01 00 00 00 00 4C D2
					0D 0D 0D 0D 0A 14 14 14 14 0A 18 18 18 18 16 20 20 20 20 1D 22 22 22 22 20
					16 16 16 16 12 1D 1D 1D 1D 0F 22 22 22 22 20 2A 2A 2A 2A 28 2B 2B 2B 2B 2A
					08 08 08 08 0F 1D 1D 1D 1D 14 2A 2A 2A 2A 18 32 32 32 32 30 34 34 34 34 32];
			mi,mdss-dsi-dc-on-command-state = "dsi_lp_mode";
			mi,mdss-dsi-dc-off-command = [
				39 01 00 00 00 00 06 F0 55 AA 52 08 00 /* Set page 0 */
				39 00 00 00 00 00 02 B2 18
				39 00 00 00 00 00 02 6F 0F
				39 00 00 00 00 00 05 B2 30 20 81 47
				39 01 00 00 00 00 25 B3 00 08 00 18 00 18 00 31 00 31 00 62 00 62 00 C0 00 C0 01 46 01 46 01 47 01 47 03 33 03 33 07 FF 07 FF 0F FF
				39 00 00 00 00 00 06 F0 55 AA 52 08 04 /* Set page 4 */
				39 01 00 00 00 00 4C D2
					20 1E 0E 0D 0A 22 20 18 14 0A 24 22 20 18 16 26 24 22 20 1D 2F 28 26 22 20
					80 24 20 16 12 70 26 24 1D 0F 64 28 26 22 20 5F 2A 28 2A 28 30 2D 2C 2B 2A
					2F 2F 20 08 0F 30 32 2C 1D 14 3D 34 2E 2A 18 48 36 2F 32 30 5F 38 36 34 32];
			mi,mdss-dsi-dc-off-command-state = "dsi_lp_mode";

			mi,mdss-dsi-timing-switch-gir-on-command = [
				15 01 00 00 00 00 02 2F 01
				15 01 00 00 00 00 02 26 04];
			mi,mdss-dsi-timing-switch-gir-on-command-state = "dsi_lp_mode";
			mi,mdss-dsi-gir-read-reg-pre-command = [
				39 01 00 00 00 00 06 F0 55 AA 52 08 00
				15 01 00 00 00 00 02 6F 3F];
			mi,mdss-dsi-gir-read-reg-pre-command-state = "dsi_lp_mode";
			mi,mdss-dsi-gir-read-reg-command = [
				06 01 00 00 00 00 02 B8 00];
			mi,mdss-dsi-gir-read-reg-command-state = "dsi_lp_mode";
			mi,mdss-dsi-gir-on-command = [
				39 00 00 00 00 00 06 F0 55 AA 52 08 08
				39 00 00 00 00 00 02 6F 07
				39 00 00 00 00 00 05 B9 00 00 00 00
				39 00 00 00 00 00 02 2F 01
				39 01 00 00 00 00 02 26 04];
			mi,mdss-dsi-gir-on-command-state = "dsi_lp_mode";
			mi,mdss-dsi-gir-off-command = [
				39 00 00 00 00 00 06 F0 55 AA 52 08 08
				39 00 00 00 00 00 02 6F 07
				39 00 00 00 00 00 05 B9 00 00 00 18
				39 00 00 00 00 00 02 2F 01
				39 01 00 00 00 00 02 26 01];
			mi,mdss-dsi-gir-off-command-state = "dsi_lp_mode";

				/* Round On */
			mi,mdss-dsi-round-on-command = [
				39 00 00 00 00 00 06 F0 55 AA 52 08 07
				39 01 00 00 00 00 03 C0 05 02
				];
				/* Round Off */
			mi,mdss-dsi-round-off-command = [
				39 00 00 00 00 00 06 F0 55 AA 52 08 07
				39 01 00 00 00 00 03 C0 00 02
				];
			mi,mdss-dsi-round-on-command-state = "dsi_lp_mode";
			mi,mdss-dsi-round-off-command-state = "dsi_lp_mode";

			mi,mdss-dsi-dim-fp-dbv-max-in-hbm-command = [
				39 01 00 00 00 00 06 F0 55 AA 52 08 00
				39 00 00 00 00 00 02 6F 17
				39 01 00 00 00 00 03 B2 0F FF
				];
			mi,mdss-dsi-dim-fp-dbv-max-in-hbm-command-state = "dsi_lp_mode";
			mi,mdss-dsi-dim-fp-dbv-max-in-normal-command = [
				39 01 00 00 00 00 06 F0 55 AA 52 08 00
				39 00 00 00 00 00 02 6F 17
				39 01 00 00 00 00 03 B2 07 FF
				];
			mi,mdss-dsi-dim-fp-dbv-max-in-normal-command-state = "dsi_lp_mode";
		};
		timing@1{
			mi,mdss-dsi-doze-hbm-command = [
				/* Enter 60Hz */
				39 01 00 00 00 00 02 2F 01
				39 01 00 00 00 00 02 26 01
				/* AOD Mode On */
				39 01 00 00 00 00 06 F0 55 AA 52 08 00
				39 01 00 00 00 00 02 B2 08
				/* 60 nit*/
				39 01 00 00 00 00 02 6F 02
				39 01 00 00 00 00 03 51 0F FF
				05 01 00 00 0A 00 02 39 00];
			mi,mdss-dsi-doze-lbm-command = [
				/* Enter 60Hz */
				39 01 00 00 00 00 02 2F 01
				39 01 00 00 00 00 02 26 01
				/* AOD Mode On */
				39 01 00 00 00 00 06 F0 55 AA 52 08 00
				39 01 00 00 00 00 02 B2 08
				/* 5 nit */
				39 01 00 00 00 00 02 6F 02
				39 01 00 00 00 00 03 51 01 55
				05 01 00 00 0A 00 02 39 00];
			mi,mdss-dsi-doze-hbm-command-state = "dsi_lp_mode";
			mi,mdss-dsi-doze-lbm-command-state = "dsi_lp_mode";

			mi,mdss-dsi-hbm-on-command = [
				/* Dimming On */
				15 00 00 00 00 00 02 53 28
				/* HBM Mode 800 nit */
				39 01 00 00 00 00 05 51 0F FF 00 00];
			mi,mdss-dsi-hbm-off-command = [
				/* Dimming On */
				15 00 00 00 00 00 02 53 28
				/* Normal Mode */
				/* parameter will be updated base on last brightness */
				39 01 00 00 00 00 05 51 07 FF 00 00];
			mi,mdss-dsi-hbm-on-command-state = "dsi_lp_mode";
			mi,mdss-dsi-hbm-off-command-state = "dsi_lp_mode";

			mi,mdss-dsi-fod-lhbm-white-1000nit-command = [
				39 01 00 00 00 00 06 F0 55 AA 52 08 00 /* Set page 0 */
				39 01 00 00 00 00 02 B2 18
				05 01 00 00 00 00 02 38 00
				39 01 00 00 00 00 06 F0 55 AA 52 08 02
				39 01 00 00 00 00 02 6F 08
				/*FPR area RGB[11:0] setting*/
				39 01 00 00 00 00 07 D0 0B 00 09 92 0B 0E
				/*FPR center postion x[11:0], y[11:0]*/
				39 01 00 00 00 00 05 88 02 1C 08 73
				/*alpha for AA*/
				39 01 00 00 00 00 03 87 0F FF
				39 01 00 00 00 00 02 6F 02
				39 01 00 00 22 00 02 87 05];
			mi,mdss-dsi-fod-lhbm-white-110nit-command = [
				39 01 00 00 00 00 06 F0 55 AA 52 08 00 /* Set page 0 */
				39 01 00 00 00 00 02 B2 18
				05 01 00 00 00 00 02 38 00
				39 01 00 00 00 00 06 F0 55 AA 52 08 02
				39 01 00 00 00 00 02 6F 08
				/*FPR area RGB[11:0] setting*/
				39 01 00 00 00 00 07 D0 07 13 06 49 07 A4
				/*FPR center postion x[11:0], y[11:0]*/
				39 01 00 00 00 00 05 88 02 1C 08 73
				/*alpha for AA*/
				39 01 00 00 00 00 03 87 0F FF
				39 01 00 00 00 00 02 6F 02
				39 01 00 00 22 00 02 87 05];
			mi,mdss-dsi-fod-lhbm-green-500nit-command = [
				39 01 00 00 00 00 06 F0 55 AA 52 08 02
				39 01 00 00 00 00 02 6F 08
				/*FPR area RGB[11:0] setting*/
				39 01 00 00 00 00 07 D0 00 00 08 A8 00 00
				/*FPR center postion x[11:0], y[11:0]*/
				39 01 00 00 00 00 05 88 02 1C 08 73
				/*alpha for AA*/
				39 01 00 00 00 00 03 87 0F FF
				39 01 00 00 00 00 02 6F 02
				39 01 00 00 22 00 02 87 05];
			mi,mdss-dsi-fod-lhbm-off-command = [
				39 01 00 00 00 00 02 6F 02
				39 01 00 00 00 00 02 87 04];
			mi,mdss-dsi-fod-lhbm-white-1000nit-command-state = "dsi_lp_mode";
			mi,mdss-dsi-fod-lhbm-white-110nit-command-state = "dsi_lp_mode";
			mi,mdss-dsi-fod-lhbm-green-500nit-command-state = "dsi_lp_mode";
			mi,mdss-dsi-fod-lhbm-off-command-state = "dsi_lp_mode";

			mi,mdss-dsi-hbm-hdr-on-command = [
				/* VI Setting voltage -3.5V */
				39 01 00 00 00 00 06 F0 55 AA 52 08 01 /* Set page 1 */
				39 00 00 00 00 00 09 B9 1F 1F 1F 1F 1F 1F 1F 1F
				/* Dimming On */
				15 00 00 00 00 00 02 53 28
				/* HBM Mode 800 nit */
				39 01 00 00 00 00 05 51 0F FF 00 00
				/* ELVSS SWIRE =-4.5V */
				15 01 00 00 00 00 02 6F 07
				15 01 00 00 00 00 02 B5 0A];
			mi,mdss-dsi-hbm-hdr-off-command = [
				/* Dimming On */
				15 01 00 00 00 00 02 53 28
				/* Normal Mode */
				/* parameter will be updated base on last brightness */
				39 01 00 00 00 00 05 51 07 FF 00 00];
			mi,mdss-dsi-hbm-hdr-on-command-state = "dsi_lp_mode";
			mi,mdss-dsi-hbm-hdr-off-command-state = "dsi_lp_mode";

			mi,mdss-dsi-dimmingon-command = [15 01 00 00 00 00 02 53 28];
			mi,mdss-dsi-dimmingon-command-state = "dsi_lp_mode";
			mi,mdss-dsi-dimmingoff-command = [15 01 00 00 00 00 02 53 20];
			mi,mdss-dsi-dimmingoff-command-state = "dsi_lp_mode";

			mi,mdss-dsi-white-point-read-command = [06 01 00 00 01 00 02 DF 00];
			mi,mdss-dsi-white-point-read-command-state = "dsi_lp_mode";

			mi,mdss-dsi-timing-switch-gir-on-command = [
				39 01 00 00 00 00 02 2F 03
				39 00 00 00 00 00 06 F0 55 AA 52 08 00
				39 00 00 00 00 00 02 6F 0A
				39 00 00 00 00 00 02 C0 41
				39 00 00 00 00 00 06 F0 55 AA 52 08 02
				39 00 00 00 00 00 02 CC 30
				39 01 00 00 0A 00 02 CE 01
				39 01 00 00 00 00 02 CC 00];
			mi,mdss-dsi-timing-switch-gir-on-command-state = "dsi_lp_mode";
			mi,mdss-dsi-gir-read-reg-pre-command = [
				39 01 00 00 00 00 06 F0 55 AA 52 08 00
				15 01 00 00 00 00 02 6F 3F];
			mi,mdss-dsi-gir-read-reg-pre-command-state = "dsi_lp_mode";
			mi,mdss-dsi-gir-read-reg-command = [
				06 01 00 00 00 00 02 B8 00];
			mi,mdss-dsi-gir-read-reg-command-state = "dsi_lp_mode";
			mi,mdss-dsi-gir-on-command = [
				39 00 00 00 00 00 06 F0 55 AA 52 08 08
				39 00 00 00 00 00 02 6F 07
				39 00 00 00 00 00 05 B9 00 00 00 00
				39 00 00 00 00 00 02 2F 03
				39 00 00 00 00 00 06 F0 55 AA 52 08 00
				39 00 00 00 00 00 02 6F 0A
				39 00 00 00 00 00 02 C0 41
				39 00 00 00 00 00 06 F0 55 AA 52 08 02
				39 00 00 00 00 00 02 CC 30
				39 01 00 00 0A 00 02 CE 01
				39 01 00 00 00 00 02 CC 00];
			mi,mdss-dsi-gir-on-command-state = "dsi_lp_mode";
			mi,mdss-dsi-gir-off-command = [
				39 00 00 00 00 00 06 F0 55 AA 52 08 08
				39 00 00 00 00 00 02 6F 07
				39 00 00 00 00 00 05 B9 00 00 00 18
				39 00 00 00 00 00 02 2F 03
				39 00 00 00 00 00 06 F0 55 AA 52 08 00
				39 00 00 00 00 00 02 6F 0A
				39 00 00 00 00 00 02 C0 01
				39 00 00 00 00 00 06 F0 55 AA 52 08 02
				39 00 00 00 00 00 02 CC 30
				39 01 00 00 0A 00 02 CE 01
				39 01 00 00 00 00 02 CC 00];
			mi,mdss-dsi-gir-off-command-state = "dsi_lp_mode";

				/* Round On */
			mi,mdss-dsi-round-on-command = [
				39 00 00 00 00 00 06 F0 55 AA 52 08 07
				39 01 00 00 00 00 03 C0 05 02
				];
				/* Round Off */
			mi,mdss-dsi-round-off-command = [
				39 00 00 00 00 00 06 F0 55 AA 52 08 07
				39 01 00 00 00 00 03 C0 00 02
				];
			mi,mdss-dsi-round-on-command-state = "dsi_lp_mode";
			mi,mdss-dsi-round-off-command-state = "dsi_lp_mode";

			mi,mdss-dsi-dim-fp-dbv-max-in-hbm-command = [
				39 01 00 00 00 00 06 F0 55 AA 52 08 00
				39 00 00 00 00 00 02 6F 17
				39 01 00 00 00 00 03 B2 0F FF
				];
			mi,mdss-dsi-dim-fp-dbv-max-in-hbm-command-state = "dsi_lp_mode";
			mi,mdss-dsi-dim-fp-dbv-max-in-normal-command = [
				39 01 00 00 00 00 06 F0 55 AA 52 08 00
				39 00 00 00 00 00 02 6F 17
				39 01 00 00 00 00 03 B2 07 FF
				];
			mi,mdss-dsi-dim-fp-dbv-max-in-normal-command-state = "dsi_lp_mode";
		};
		timing@2{
			mi,mdss-dsi-doze-hbm-command = [
				/* Enter 60Hz */
				39 01 00 00 00 00 02 2F 01
				39 01 00 00 00 00 02 26 01
				/* AOD Mode On */
				39 01 00 00 00 00 06 F0 55 AA 52 08 00
				39 01 00 00 00 00 02 B2 08
				/* 60 nit */
				39 01 00 00 00 00 02 6F 02
				39 01 00 00 00 00 03 51 0F FF
				05 01 00 00 0A 00 02 39 00];
			mi,mdss-dsi-doze-lbm-command = [
				/* Enter 60Hz */
				39 01 00 00 00 00 02 2F 01
				39 01 00 00 00 00 02 26 01
				/* AOD Mode On */
				39 01 00 00 00 00 06 F0 55 AA 52 08 00
				39 01 00 00 00 00 02 B2 08
				/* 5 nit */
				39 01 00 00 00 00 02 6F 02
				39 01 00 00 00 00 03 51 01 55
				05 01 00 00 0A 00 02 39 00];
			mi,mdss-dsi-doze-hbm-command-state = "dsi_lp_mode";
			mi,mdss-dsi-doze-lbm-command-state = "dsi_lp_mode";

			mi,mdss-dsi-hbm-on-command = [
				/* Dimming On */
				15 00 00 00 00 00 02 53 28
				/* HBM Mode 800 nit */
				39 01 00 00 00 00 05 51 0F FF 00 00];
			mi,mdss-dsi-hbm-off-command = [
				/* Dimming On */
				15 00 00 00 00 00 02 53 28
				/* Normal Mode */
				/* parameter will be updated base on last brightness */
				39 01 00 00 00 00 05 51 07 FF 00 00];
			mi,mdss-dsi-hbm-on-command-state = "dsi_lp_mode";
			mi,mdss-dsi-hbm-off-command-state = "dsi_lp_mode";

			mi,mdss-dsi-fod-lhbm-white-1000nit-command = [
				39 01 00 00 00 00 06 F0 55 AA 52 08 00 /* Set page 0 */
				39 01 00 00 00 00 02 B2 18
				05 01 00 00 00 00 02 38 00
				39 01 00 00 00 00 06 F0 55 AA 52 08 02
				39 01 00 00 00 00 02 6F 08
				/*FPR area RGB[11:0] setting*/
				39 01 00 00 00 00 07 D0 0B 00 09 92 0B 0E
				/*FPR center postion x[11:0], y[11:0]*/
				39 01 00 00 00 00 05 88 02 1C 08 73
				/*alpha for AA*/
				39 01 00 00 00 00 03 87 0F FF
				39 01 00 00 00 00 02 6F 02
				39 01 00 00 19 00 02 87 05];
			mi,mdss-dsi-fod-lhbm-white-110nit-command = [
				39 01 00 00 00 00 06 F0 55 AA 52 08 00 /* Set page 0 */
				39 01 00 00 00 00 02 B2 18
				05 01 00 00 00 00 02 38 00
				39 01 00 00 00 00 06 F0 55 AA 52 08 02
				39 01 00 00 00 00 02 6F 08
				/*FPR area RGB[11:0] setting*/
				39 01 00 00 00 00 07 D0 07 13 06 49 07 A4
				/*FPR center postion x[11:0], y[11:0]*/
				39 01 00 00 00 00 05 88 02 1C 08 73
				/*alpha for AA*/
				39 01 00 00 00 00 03 87 0F FF
				39 01 00 00 00 00 02 6F 02
				39 01 00 00 19 00 02 87 05];
			mi,mdss-dsi-fod-lhbm-green-500nit-command = [
				39 01 00 00 00 00 06 F0 55 AA 52 08 02
				39 01 00 00 00 00 02 6F 08
				/*FPR area RGB[11:0] setting*/
				39 01 00 00 00 00 07 D0 00 00 08 A8 00 00
				/*FPR center postion x[11:0], y[11:0]*/
				39 01 00 00 00 00 05 88 02 1C 08 73
				/*alpha for AA*/
				39 01 00 00 00 00 03 87 0F FF
				39 01 00 00 00 00 02 6F 02
				39 01 00 00 19 00 02 87 05];
			mi,mdss-dsi-fod-lhbm-off-command = [
				39 01 00 00 00 00 02 6F 02
				39 01 00 00 00 00 02 87 04];
			mi,mdss-dsi-fod-lhbm-white-1000nit-command-state = "dsi_lp_mode";
			mi,mdss-dsi-fod-lhbm-white-110nit-command-state = "dsi_lp_mode";
			mi,mdss-dsi-fod-lhbm-green-500nit-command-state = "dsi_lp_mode";
			mi,mdss-dsi-fod-lhbm-off-command-state = "dsi_lp_mode";

			mi,mdss-dsi-hbm-hdr-on-command = [
				/* VI Setting voltage -3.5V */
				39 01 00 00 00 00 06 F0 55 AA 52 08 01 /* Set page 1 */
				39 00 00 00 00 00 09 B9 1F 1F 1F 1F 1F 1F 1F 1F
				/* Dimming On */
				15 00 00 00 00 00 02 53 28
				/* HBM Mode 800 nit */
				39 01 00 00 00 00 05 51 0F FF 00 00
				/* ELVSS SWIRE =-4.5V */
				15 01 00 00 00 00 02 6F 07
				15 01 00 00 00 00 02 B5 0A];
			mi,mdss-dsi-hbm-hdr-off-command = [
				/* Dimming On */
				15 01 00 00 00 00 02 53 28
				/* Normal Mode */
				/* parameter will be updated base on last brightness */
				39 01 00 00 00 00 05 51 07 FF 00 00];
			mi,mdss-dsi-hbm-hdr-on-command-state = "dsi_lp_mode";
			mi,mdss-dsi-hbm-hdr-off-command-state = "dsi_lp_mode";

			mi,mdss-dsi-dimmingon-command = [15 01 00 00 00 00 02 53 28];
			mi,mdss-dsi-dimmingon-command-state = "dsi_lp_mode";
			mi,mdss-dsi-dimmingoff-command = [15 01 00 00 00 00 02 53 20];
			mi,mdss-dsi-dimmingoff-command-state = "dsi_lp_mode";

			mi,mdss-dsi-white-point-read-command = [06 01 00 00 01 00 02 DF 00];
			mi,mdss-dsi-white-point-read-command-state = "dsi_lp_mode";

			mi,mdss-dsi-timing-switch-gir-on-command = [
				39 01 00 00 00 00 02 2F 02
				39 00 00 00 00 00 06 F0 55 AA 52 08 00
				39 00 00 00 00 00 02 6F 09
				39 00 00 00 00 00 02 C0 60
				39 00 00 00 00 00 06 F0 55 AA 52 08 02
				39 00 00 00 00 00 02 CC 30
				39 01 00 00 0A 00 02 CE 01
				39 01 00 00 00 00 02 CC 00];
			mi,mdss-dsi-timing-switch-gir-on-command-state = "dsi_lp_mode";
			mi,mdss-dsi-gir-read-reg-pre-command = [
				39 01 00 00 00 00 06 F0 55 AA 52 08 00
				15 01 00 00 00 00 02 6F 3F];
			mi,mdss-dsi-gir-read-reg-pre-command-state = "dsi_lp_mode";
			mi,mdss-dsi-gir-read-reg-command = [
				06 01 00 00 00 00 02 B8 00];
			mi,mdss-dsi-gir-read-reg-command-state = "dsi_lp_mode";
			mi,mdss-dsi-gir-on-command = [
				39 00 00 00 00 00 06 F0 55 AA 52 08 08
				39 00 00 00 00 00 02 6F 07
				39 00 00 00 00 00 05 B9 00 00 00 00
				39 00 00 00 00 00 02 2F 02
				39 00 00 00 00 00 06 F0 55 AA 52 08 00
				39 00 00 00 00 00 02 6F 09
				39 00 00 00 00 00 02 C0 60
				39 00 00 00 00 00 06 F0 55 AA 52 08 02
				39 00 00 00 00 00 02 CC 30
				39 01 00 00 0A 00 02 CE 01
				39 01 00 00 00 00 02 CC 00];
			mi,mdss-dsi-gir-on-command-state = "dsi_lp_mode";
			mi,mdss-dsi-gir-off-command = [
				39 00 00 00 00 00 06 F0 55 AA 52 08 08
				39 00 00 00 00 00 02 6F 07
				39 00 00 00 00 00 05 B9 00 00 00 18
				39 00 00 00 00 00 02 2F 02
				39 00 00 00 00 00 06 F0 55 AA 52 08 00
				39 00 00 00 00 00 02 6F 09
				39 00 00 00 00 00 02 C0 20
				39 00 00 00 00 00 06 F0 55 AA 52 08 02
				39 00 00 00 00 00 02 CC 30
				39 01 00 00 0A 00 02 CE 01
				39 01 00 00 00 00 02 CC 00];
			mi,mdss-dsi-gir-off-command-state = "dsi_lp_mode";

				/* Round On */
			mi,mdss-dsi-round-on-command = [
				39 00 00 00 00 00 06 F0 55 AA 52 08 07
				39 01 00 00 00 00 03 C0 05 02
				];
				/* Round Off */
			mi,mdss-dsi-round-off-command = [
				39 00 00 00 00 00 06 F0 55 AA 52 08 07
				39 01 00 00 00 00 03 C0 00 02
				];
			mi,mdss-dsi-round-on-command-state = "dsi_lp_mode";
			mi,mdss-dsi-round-off-command-state = "dsi_lp_mode";

			mi,mdss-dsi-dim-fp-dbv-max-in-hbm-command = [
				39 01 00 00 00 00 06 F0 55 AA 52 08 00
				39 00 00 00 00 00 02 6F 17
				39 01 00 00 00 00 03 B2 0F FF
				];
			mi,mdss-dsi-dim-fp-dbv-max-in-hbm-command-state = "dsi_lp_mode";
			mi,mdss-dsi-dim-fp-dbv-max-in-normal-command = [
				39 01 00 00 00 00 06 F0 55 AA 52 08 00
				39 00 00 00 00 00 02 6F 17
				39 01 00 00 00 00 03 B2 07 FF
				];
			mi,mdss-dsi-dim-fp-dbv-max-in-normal-command-state = "dsi_lp_mode";
		};
	};
};

